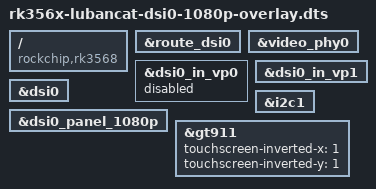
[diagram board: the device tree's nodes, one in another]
/dts-v1/;
/plugin/;

/ {
	compatible = "rockchip,rk3568";

	fragment@0 {
		target = <&route_dsi0>;

		__overlay__ {
			status = "okay";
		};
	};

	fragment@1 {
		target = <&video_phy0>;

		__overlay__ {
			status = "okay";
		};
	};

	fragment@2 {
		target = <&dsi0_in_vp0>;

		__overlay__ {
			status = "disabled";
		};
	};

	fragment@3 {
		target = <&dsi0_in_vp1>;

		__overlay__ {
			status = "okay";
		};
	};

	fragment@4 {
		target = <&dsi0>;

		__overlay__ {
			status = "okay";
		};
	};

	fragment@5 {
		target = <&dsi0_panel_1080p>;

		__overlay__ {
			status = "okay";
		};
	};

	fragment@6 {
		target = <&i2c1>;

		__overlay__ {
			status = "okay";
		};
	};

	fragment@7 {
		target = <&gt911>;

		__overlay__ {
			status = "okay";
			touchscreen-inverted-x = <1>;
			touchscreen-inverted-y = <1>;
		};
	};
};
